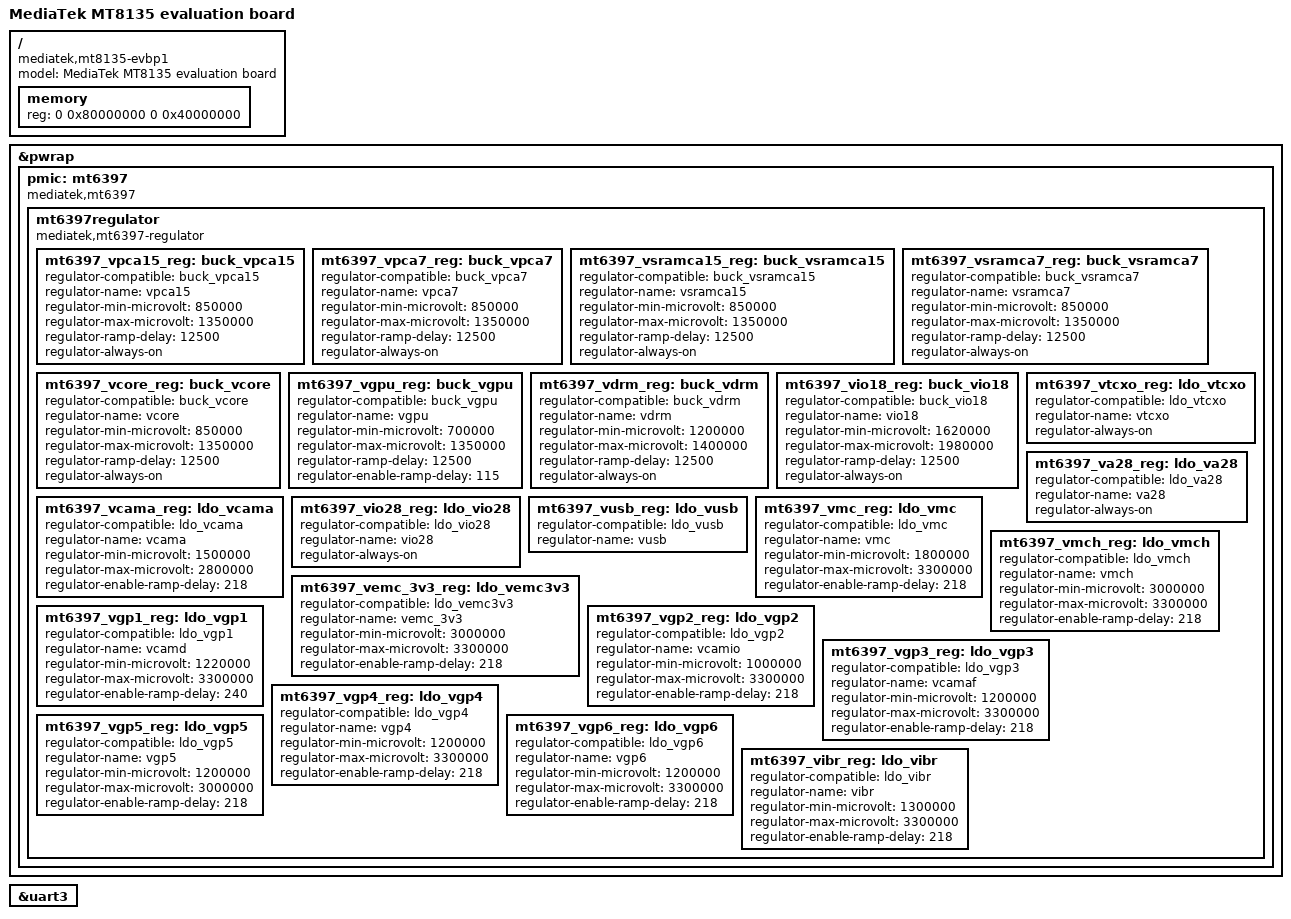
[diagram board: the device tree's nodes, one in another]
/*
 * Copyright (c) 2014 MediaTek Inc.
 * Author: Joe.C <yingjoe.chen@mediatek.com>
 *
 * This program is free software; you can redistribute it and/or modify
 * it under the terms of the GNU General Public License version 2 as
 * published by the Free Software Foundation.
 *
 * This program is distributed in the hope that it will be useful,
 * but WITHOUT ANY WARRANTY; without even the implied warranty of
 * MERCHANTABILITY or FITNESS FOR A PARTICULAR PURPOSE.  See the
 * GNU General Public License for more details.
 */

/dts-v1/;
#include "mt8135.dtsi"

/ {
	model = "MediaTek MT8135 evaluation board";
	compatible = "mediatek,mt8135-evbp1", "mediatek,mt8135";

	memory {
		reg = <0 0x80000000 0 0x40000000>;
	};
};

&pwrap {
	pmic: mt6397 {
		compatible = "mediatek,mt6397";

		mt6397regulator: mt6397regulator {
			compatible = "mediatek,mt6397-regulator";

			mt6397_vpca15_reg: buck_vpca15 {
				regulator-compatible = "buck_vpca15";
				regulator-name = "vpca15";
				regulator-min-microvolt = < 850000>;
				regulator-max-microvolt = <1350000>;
				regulator-ramp-delay = <12500>;
				regulator-always-on;
			};

			mt6397_vpca7_reg: buck_vpca7 {
				regulator-compatible = "buck_vpca7";
				regulator-name = "vpca7";
				regulator-min-microvolt = < 850000>;
				regulator-max-microvolt = <1350000>;
				regulator-ramp-delay = <12500>;
				regulator-always-on;
			};

			mt6397_vsramca15_reg: buck_vsramca15 {
				regulator-compatible = "buck_vsramca15";
				regulator-name = "vsramca15";
				regulator-min-microvolt = < 850000>;
				regulator-max-microvolt = <1350000>;
				regulator-ramp-delay = <12500>;
				regulator-always-on;
			};

			mt6397_vsramca7_reg: buck_vsramca7 {
				regulator-compatible = "buck_vsramca7";
				regulator-name = "vsramca7";
				regulator-min-microvolt = < 850000>;
				regulator-max-microvolt = <1350000>;
				regulator-ramp-delay = <12500>;
				regulator-always-on;
			};

			mt6397_vcore_reg: buck_vcore {
				regulator-compatible = "buck_vcore";
				regulator-name = "vcore";
				regulator-min-microvolt = < 850000>;
				regulator-max-microvolt = <1350000>;
				regulator-ramp-delay = <12500>;
				regulator-always-on;
			};

			mt6397_vgpu_reg: buck_vgpu {
				regulator-compatible = "buck_vgpu";
				regulator-name = "vgpu";
				regulator-min-microvolt = < 700000>;
				regulator-max-microvolt = <1350000>;
				regulator-ramp-delay = <12500>;
				regulator-enable-ramp-delay = <115>;
			};

			mt6397_vdrm_reg: buck_vdrm {
				regulator-compatible = "buck_vdrm";
				regulator-name = "vdrm";
				regulator-min-microvolt = <1200000>;
				regulator-max-microvolt = <1400000>;
				regulator-ramp-delay = <12500>;
				regulator-always-on;
			};

			mt6397_vio18_reg: buck_vio18 {
				regulator-compatible = "buck_vio18";
				regulator-name = "vio18";
				regulator-min-microvolt = <1620000>;
				regulator-max-microvolt = <1980000>;
				regulator-ramp-delay = <12500>;
				regulator-always-on;
			};

			mt6397_vtcxo_reg: ldo_vtcxo {
				regulator-compatible = "ldo_vtcxo";
				regulator-name = "vtcxo";
				regulator-always-on;
			};

			mt6397_va28_reg: ldo_va28 {
				regulator-compatible = "ldo_va28";
				regulator-name = "va28";
				regulator-always-on;
			};

			mt6397_vcama_reg: ldo_vcama {
				regulator-compatible = "ldo_vcama";
				regulator-name = "vcama";
				regulator-min-microvolt = <1500000>;
				regulator-max-microvolt = <2800000>;
				regulator-enable-ramp-delay = <218>;
			};

			mt6397_vio28_reg: ldo_vio28 {
				regulator-compatible = "ldo_vio28";
				regulator-name = "vio28";
				regulator-always-on;
			};

			mt6397_vusb_reg: ldo_vusb {
				regulator-compatible = "ldo_vusb";
				regulator-name = "vusb";
			};

			mt6397_vmc_reg: ldo_vmc {
				regulator-compatible = "ldo_vmc";
				regulator-name = "vmc";
				regulator-min-microvolt = <1800000>;
				regulator-max-microvolt = <3300000>;
				regulator-enable-ramp-delay = <218>;
			};

			mt6397_vmch_reg: ldo_vmch {
				regulator-compatible = "ldo_vmch";
				regulator-name = "vmch";
				regulator-min-microvolt = <3000000>;
				regulator-max-microvolt = <3300000>;
				regulator-enable-ramp-delay = <218>;
			};

			mt6397_vemc_3v3_reg: ldo_vemc3v3 {
				regulator-compatible = "ldo_vemc3v3";
				regulator-name = "vemc_3v3";
				regulator-min-microvolt = <3000000>;
				regulator-max-microvolt = <3300000>;
				regulator-enable-ramp-delay = <218>;
			};

			mt6397_vgp1_reg: ldo_vgp1 {
				regulator-compatible = "ldo_vgp1";
				regulator-name = "vcamd";
				regulator-min-microvolt = <1220000>;
				regulator-max-microvolt = <3300000>;
				regulator-enable-ramp-delay = <240>;
			};

			mt6397_vgp2_reg: ldo_vgp2 {
				regulator-compatible = "ldo_vgp2";
				regulator-name = "vcamio";
				regulator-min-microvolt = <1000000>;
				regulator-max-microvolt = <3300000>;
				regulator-enable-ramp-delay = <218>;
			};

			mt6397_vgp3_reg: ldo_vgp3 {
				regulator-compatible = "ldo_vgp3";
				regulator-name = "vcamaf";
				regulator-min-microvolt = <1200000>;
				regulator-max-microvolt = <3300000>;
				regulator-enable-ramp-delay = <218>;
			};

			mt6397_vgp4_reg: ldo_vgp4 {
				regulator-compatible = "ldo_vgp4";
				regulator-name = "vgp4";
				regulator-min-microvolt = <1200000>;
				regulator-max-microvolt = <3300000>;
				regulator-enable-ramp-delay = <218>;
			};

			mt6397_vgp5_reg: ldo_vgp5 {
				regulator-compatible = "ldo_vgp5";
				regulator-name = "vgp5";
				regulator-min-microvolt = <1200000>;
				regulator-max-microvolt = <3000000>;
				regulator-enable-ramp-delay = <218>;
			};

			mt6397_vgp6_reg: ldo_vgp6 {
				regulator-compatible = "ldo_vgp6";
				regulator-name = "vgp6";
				regulator-min-microvolt = <1200000>;
				regulator-max-microvolt = <3300000>;
				regulator-enable-ramp-delay = <218>;
			};

			mt6397_vibr_reg: ldo_vibr {
				regulator-compatible = "ldo_vibr";
				regulator-name = "vibr";
				regulator-min-microvolt = <1300000>;
				regulator-max-microvolt = <3300000>;
				regulator-enable-ramp-delay = <218>;
			};
		};
	};
};

&uart3 {
	status = "okay";
};
